VERSION ""

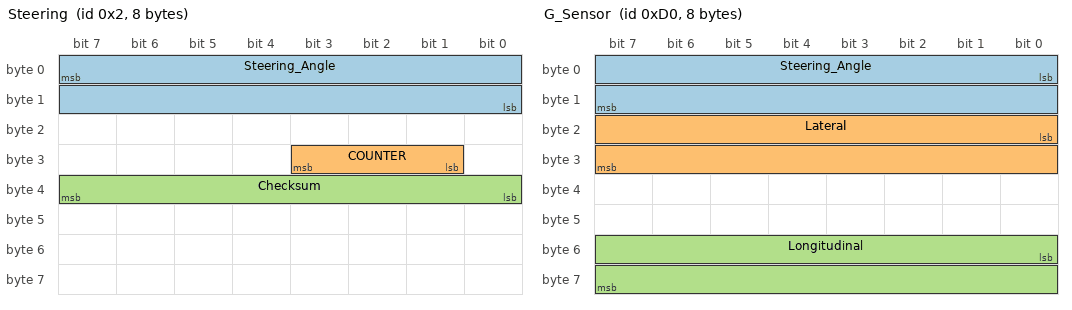
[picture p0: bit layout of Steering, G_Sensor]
BO_ 2 Steering: 8 XXX
 SG_ Steering_Angle : 7|16@0- (0.1,0) [-500|500] "degree" XXX
 SG_ COUNTER : 27|3@0+ (1,0) [0|7] "" XXX
 SG_ Checksum : 39|8@0+ (1,0) [0|255] "" XXX

BO_ 208 G_Sensor: 8 XXX
 SG_ Steering_Angle : 0|16@1- (-0.1,0) [-500|500] "" XXX
 SG_ Lateral : 16|16@1- (-0.0035,1) [-255|255] "" XXX
 SG_ Longitudinal : 48|16@1- (-0.00035,0) [-255|255] "" XXX

BO_ 209 Brake_Pedal: 8 XXX
 SG_ Speed : 0|16@1+ (0.05625,0) [0|255] "KPH" XXX
 SG_ Brake_Pedal : 16|8@1+ (1,0) [0|255] "" XXX

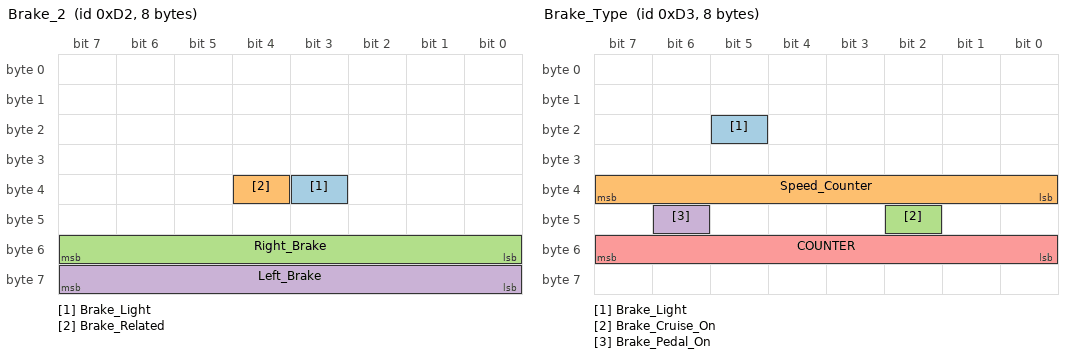
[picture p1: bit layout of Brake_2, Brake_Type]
BO_ 210 Brake_2: 8 XXX
 SG_ Brake_Light : 35|1@1+ (1,0) [0|1] "" XXX
 SG_ Brake_Related : 36|1@1+ (1,0) [0|1] "" XXX
 SG_ Right_Brake : 48|8@1+ (1,0) [0|255] "" XXX
 SG_ Left_Brake : 56|8@1+ (1,0) [0|255] "" XXX

BO_ 211 Brake_Type: 8 XXX
 SG_ Brake_Light : 21|1@1+ (1,0) [0|1] "" XXX
 SG_ Speed_Counter : 32|8@1+ (1,0) [0|255] "" XXX
 SG_ Brake_Cruise_On : 42|1@1+ (1,0) [0|1] "" XXX
 SG_ Brake_Pedal_On : 46|1@1+ (1,0) [0|1] "" XXX
 SG_ COUNTER : 48|8@1+ (1,0) [0|255] "" XXX

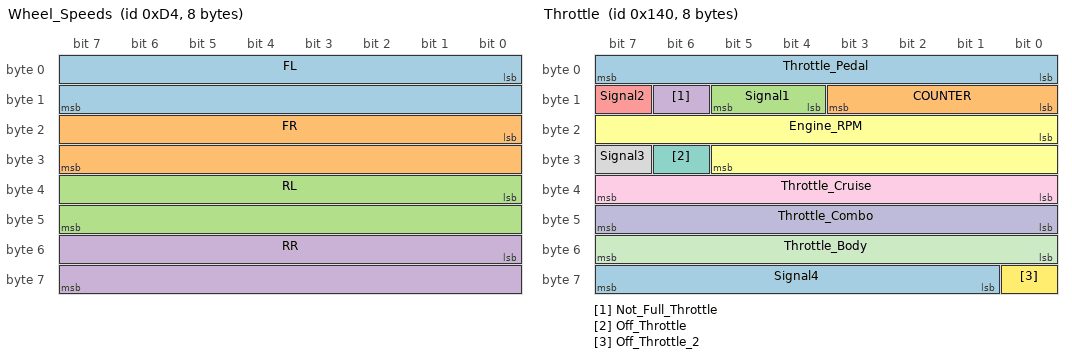
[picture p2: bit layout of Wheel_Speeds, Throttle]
BO_ 212 Wheel_Speeds: 8 XXX
 SG_ FL : 0|16@1+ (0.0592,0) [0|255] "KPH" XXX
 SG_ FR : 16|16@1+ (0.0592,0) [0|255] "KPH" XXX
 SG_ RL : 32|16@1+ (0.0592,0) [0|255] "KPH" XXX
 SG_ RR : 48|16@1+ (0.0592,0) [0|255] "KPH" XXX

BO_ 320 Throttle: 8 XXX
 SG_ Throttle_Pedal : 0|8@1+ (0.392157,0) [0|255] "" XXX
 SG_ COUNTER : 8|4@1+ (1,0) [0|15] "" XXX
 SG_ Signal1 : 12|2@1+ (1,0) [0|7] "" XXX
 SG_ Not_Full_Throttle : 14|1@1+ (1,0) [0|1] "" XXX
 SG_ Signal2 : 15|1@1+ (1,0) [0|1] "" XXX
 SG_ Engine_RPM : 16|14@1+ (1,0) [0|32767] "" XXX
 SG_ Off_Throttle : 30|1@1+ (1,0) [0|1] "" XXX
 SG_ Signal3 : 31|1@1+ (1,0) [0|1] "" XXX
 SG_ Throttle_Cruise : 32|8@1+ (1,0) [0|255] "" XXX
 SG_ Throttle_Combo : 40|8@1+ (1,0) [0|255] "" XXX
 SG_ Throttle_Body : 48|8@1+ (1,0) [0|255] "" XXX
 SG_ Off_Throttle_2 : 56|1@1+ (1,0) [0|1] "" XXX
 SG_ Signal4 : 57|7@1+ (1,0) [0|127] "" XXX

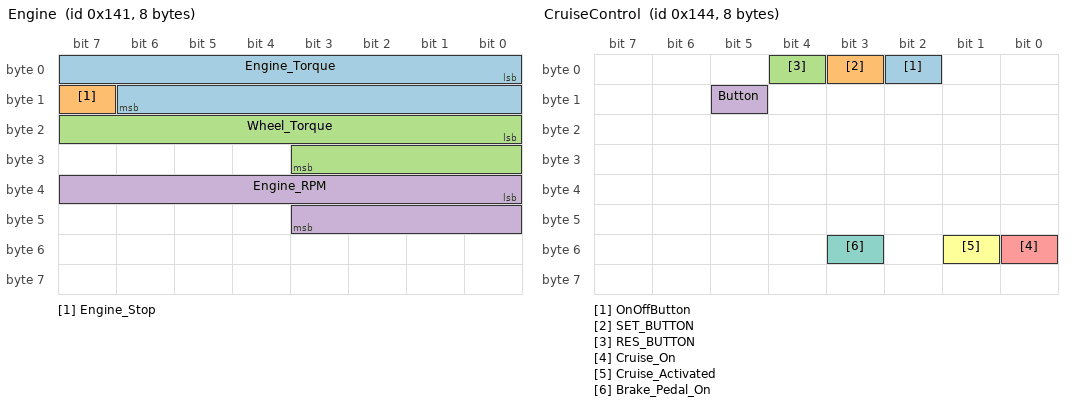
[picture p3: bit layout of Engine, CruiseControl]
BO_ 321 Engine: 8 XXX
 SG_ Engine_Torque : 0|15@1+ (1,0) [0|255] "" XXX
 SG_ Engine_Stop : 15|1@1+ (1,0) [0|1] "" XXX
 SG_ Wheel_Torque : 16|12@1+ (1,0) [0|4095] "" XXX
 SG_ Engine_RPM : 32|12@1+ (1,0) [0|8191] "" XXX

BO_ 324 CruiseControl: 8 XXX
 SG_ OnOffButton : 2|1@1+ (1,0) [0|1] "" XXX
 SG_ SET_BUTTON : 3|1@1+ (1,0) [0|1] "" XXX
 SG_ RES_BUTTON : 4|1@1+ (1,0) [0|1] "" XXX
 SG_ Button : 13|1@1+ (1,0) [0|1] "" XXX
 SG_ Cruise_On : 48|1@1+ (1,0) [0|1] "" XXX
 SG_ Cruise_Activated : 49|1@1+ (1,0) [0|1] "" XXX
 SG_ Brake_Pedal_On : 51|1@1+ (1,0) [0|1] "" XXX

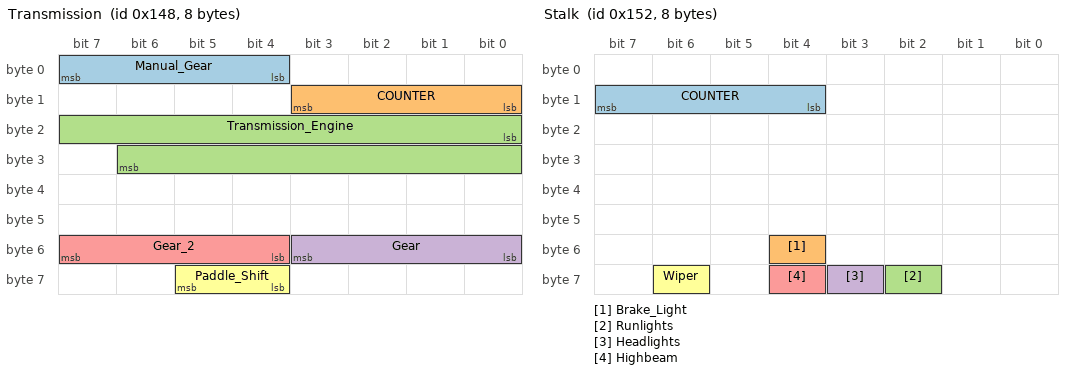
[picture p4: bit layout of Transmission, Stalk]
BO_ 328 Transmission: 8 XXX
 SG_ Manual_Gear : 4|4@1+ (1,0) [0|15] "" XXX
 SG_ COUNTER : 8|4@1+ (1,0) [0|15] "" XXX
 SG_ Transmission_Engine : 16|15@1+ (1,0) [0|65535] "" XXX
 SG_ Gear : 48|4@1+ (1,0) [0|15] "" XXX
 SG_ Gear_2 : 52|4@1+ (1,0) [0|15] "" XXX
 SG_ Paddle_Shift : 60|2@1+ (1,0) [0|3] "" XXX

BO_ 329 CVT_Ratio: 8 XXX

BO_ 336 Brake_Pressure: 8 XXX
 SG_ Brake_Pressure_Right : 0|8@1+ (1,0) [0|255] "" XXX
 SG_ Brake_Pressure_Left : 8|8@1+ (1,0) [0|255] "" XXX

BO_ 338 Stalk: 8 XXX
 SG_ COUNTER : 12|4@1+ (1,0) [0|15] "" XXX
 SG_ Brake_Light : 52|1@1+ (1,0) [0|1] "" XXX
 SG_ Runlights : 58|1@1+ (1,0) [0|1] "" XXX
 SG_ Headlights : 59|1@1+ (1,0) [0|1] "" XXX
 SG_ Highbeam : 60|1@1+ (1,0) [0|1] "" XXX
 SG_ Wiper : 62|1@1+ (1,0) [0|1] "" XXX

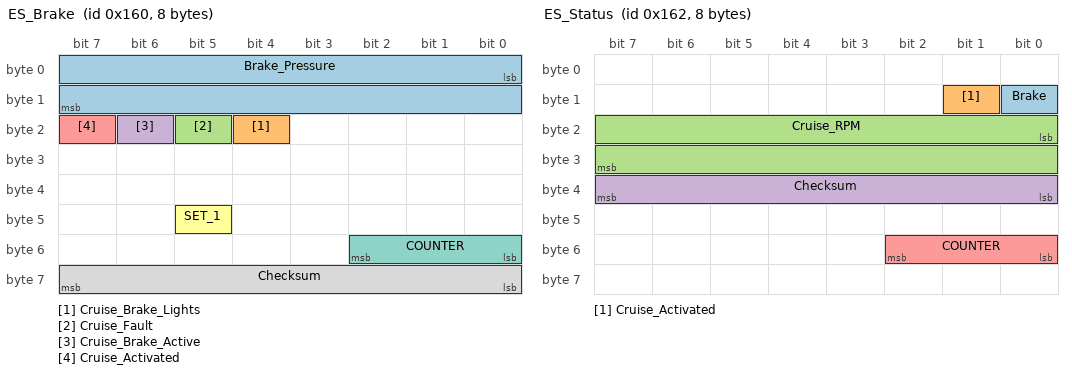
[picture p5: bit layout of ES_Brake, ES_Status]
BO_ 352 ES_Brake: 8 XXX
 SG_ Brake_Pressure : 0|16@1+ (1,0) [0|255] "" XXX
 SG_ Cruise_Brake_Lights : 20|1@1+ (1,0) [0|1] "" XXX
 SG_ Cruise_Fault : 21|1@1+ (1,0) [0|1] "" XXX
 SG_ Cruise_Brake_Active : 22|1@1+ (1,0) [0|1] "" XXX
 SG_ Cruise_Activated : 23|1@1+ (1,0) [0|1] "" XXX
 SG_ SET_1 : 45|1@0+ (1,0) [0|1] "" XXX
 SG_ COUNTER : 48|3@1+ (1,0) [0|7] "" XXX
 SG_ Checksum : 56|8@1+ (1,0) [0|255] "" XXX

BO_ 353 ES_Distance: 8 XXX
 SG_ Cruise_Throttle : 0|12@1+ (1,0) [0|4095] "" XXX
 SG_ Signal1 : 12|4@1+ (1,0) [0|15] "" XXX
 SG_ Car_Follow : 16|1@1+ (1,0) [0|1] "" XXX
 SG_ Signal2 : 17|3@1+ (1,0) [0|7] "" XXX
 SG_ Cruise_Brake_Active : 20|1@1+ (1,0) [0|1] "" XXX
 SG_ Distance_Swap : 21|1@1+ (1,0) [0|1] "" XXX
 SG_ Standstill : 22|1@1+ (1,0) [0|1] "" XXX
 SG_ Signal3 : 23|1@1+ (1,0) [0|1] "" XXX
 SG_ Close_Distance : 24|8@1+ (0.019607,0) [0|5] "m" XXX
 SG_ Signal4 : 32|9@1+ (1,0) [0|255] "" XXX
 SG_ Standstill_2 : 41|1@1+ (1,0) [0|1] "" XXX
 SG_ Cruise_Fault : 42|1@1+ (1,0) [0|1] "" XXX
 SG_ Signal5 : 43|1@1+ (1,0) [0|1] "" XXX
 SG_ COUNTER : 44|3@1+ (1,0) [0|7] "" XXX
 SG_ Signal6 : 47|1@1+ (1,0) [0|1] "" XXX
 SG_ Cruise_Button : 48|3@1+ (1,0) [0|7] "" XXX
 SG_ Signal7 : 51|5@1+ (1,0) [0|31] "" XXX
 SG_ Checksum : 56|8@1+ (1,0) [0|255] "" XXX

BO_ 354 ES_Status: 8 XXX
 SG_ Brake : 8|1@1+ (1,0) [0|1] "" XXX
 SG_ Cruise_Activated : 9|1@1+ (1,0) [0|1] "" XXX
 SG_ Cruise_RPM : 16|16@1+ (1,0) [0|65535] "" XXX
 SG_ Checksum : 32|8@1+ (1,0) [0|255] "" XXX
 SG_ COUNTER : 48|3@1+ (1,0) [0|7] "" XXX

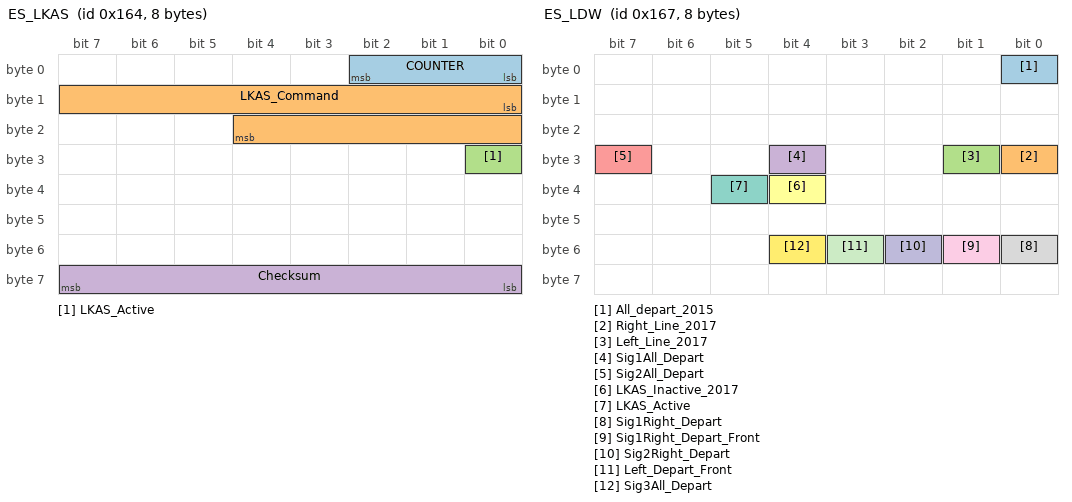
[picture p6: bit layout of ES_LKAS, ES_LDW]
BO_ 356 ES_LKAS: 8 XXX
 SG_ COUNTER : 0|3@1+ (1,0) [0|7] "" XXX
 SG_ LKAS_Command : 8|13@1- (-1,0) [-4096|4096] "" XXX
 SG_ LKAS_Active : 24|1@1+ (1,0) [0|1] "" XXX
 SG_ Checksum : 56|8@1+ (1,0) [0|255] "" XXX

BO_ 359 ES_LDW: 8 XXX
 SG_ All_depart_2015 : 0|1@1+ (1,0) [0|1] "" XXX
 SG_ Right_Line_2017 : 24|1@1+ (1,0) [0|1] "" XXX
 SG_ Left_Line_2017 : 25|1@1+ (1,0) [0|1] "" XXX
 SG_ Sig1All_Depart : 28|1@1+ (1,0) [0|1] "" XXX
 SG_ Sig2All_Depart : 31|1@1+ (1,0) [0|1] "" XXX
 SG_ LKAS_Inactive_2017 : 36|1@1+ (1,0) [0|1] "" XXX
 SG_ LKAS_Active : 37|1@1+ (1,0) [0|1] "" XXX
 SG_ Sig1Right_Depart : 48|1@1+ (1,0) [0|1] "" XXX
 SG_ Sig1Right_Depart_Front : 49|1@1+ (1,0) [0|1] "" XXX
 SG_ Sig2Right_Depart : 50|1@1+ (1,0) [0|1] "" XXX
 SG_ Left_Depart_Front : 51|1@1+ (1,0) [0|1] "" XXX
 SG_ Sig3All_Depart : 52|1@1+ (1,0) [0|1] "" XXX

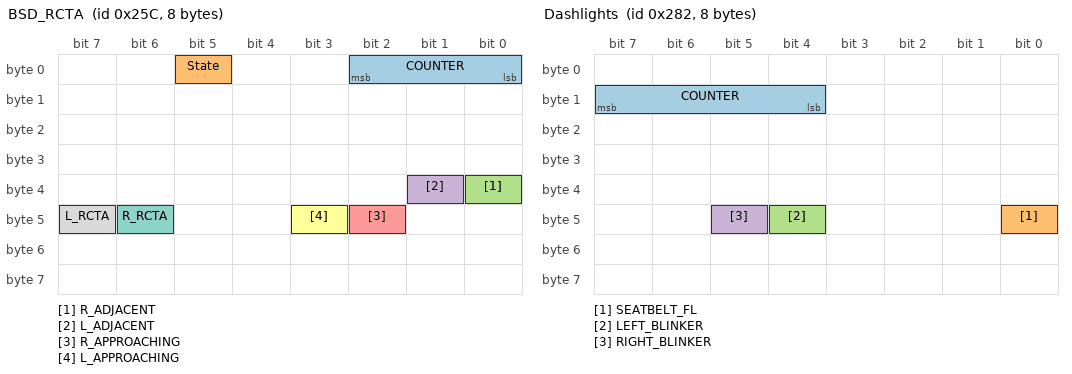
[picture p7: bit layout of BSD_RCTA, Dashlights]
BO_ 604 BSD_RCTA: 8 XXX
 SG_ COUNTER : 0|3@1+ (1,0) [0|7] "" XXX
 SG_ State : 5|1@1+ (1,0) [0|1] "" XXX
 SG_ R_ADJACENT : 32|1@1+ (1,0) [0|1] "" XXX
 SG_ L_ADJACENT : 33|1@1+ (1,0) [0|1] "" XXX
 SG_ R_APPROACHING : 42|1@1+ (1,0) [0|1] "" XXX
 SG_ L_APPROACHING : 43|1@1+ (1,0) [0|1] "" XXX
 SG_ R_RCTA : 46|1@1+ (1,0) [0|1] "" XXX
 SG_ L_RCTA : 47|1@1+ (1,0) [0|1] "" XXX

BO_ 642 Dashlights: 8 XXX
 SG_ COUNTER : 12|4@1+ (1,0) [0|15] "" XXX
 SG_ SEATBELT_FL : 40|1@1+ (1,0) [0|1] "" XXX
 SG_ LEFT_BLINKER : 44|1@1+ (1,0) [0|1] "" XXX
 SG_ RIGHT_BLINKER : 45|1@1+ (1,0) [0|1] "" XXX

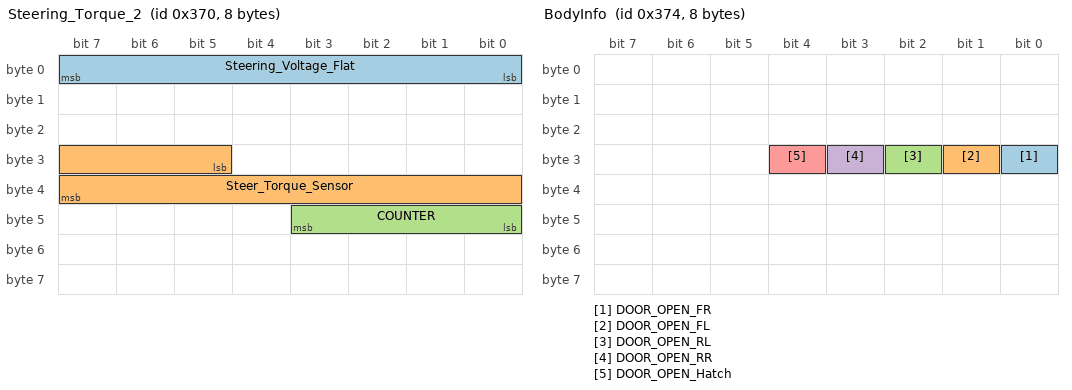
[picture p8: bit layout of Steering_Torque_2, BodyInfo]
BO_ 880 Steering_Torque_2: 8 XXX
 SG_ Steering_Voltage_Flat : 0|8@1+ (1,0) [0|255] "" XXX
 SG_ Steer_Torque_Sensor : 29|11@1- (-1,0) [-1000|1000] "" XXX
 SG_ COUNTER : 40|4@1+ (1,0) [0|15] "" XXX

BO_ 884 BodyInfo: 8 XXX
 SG_ DOOR_OPEN_FR : 24|1@1+ (1,0) [0|1] "" XXX
 SG_ DOOR_OPEN_FL : 25|1@1+ (1,0) [0|1] "" XXX
 SG_ DOOR_OPEN_RL : 26|1@1+ (1,0) [0|1] "" XXX
 SG_ DOOR_OPEN_RR : 27|1@1+ (1,0) [0|1] "" XXX
 SG_ DOOR_OPEN_Hatch : 28|1@1+ (1,0) [0|1] "" XXX

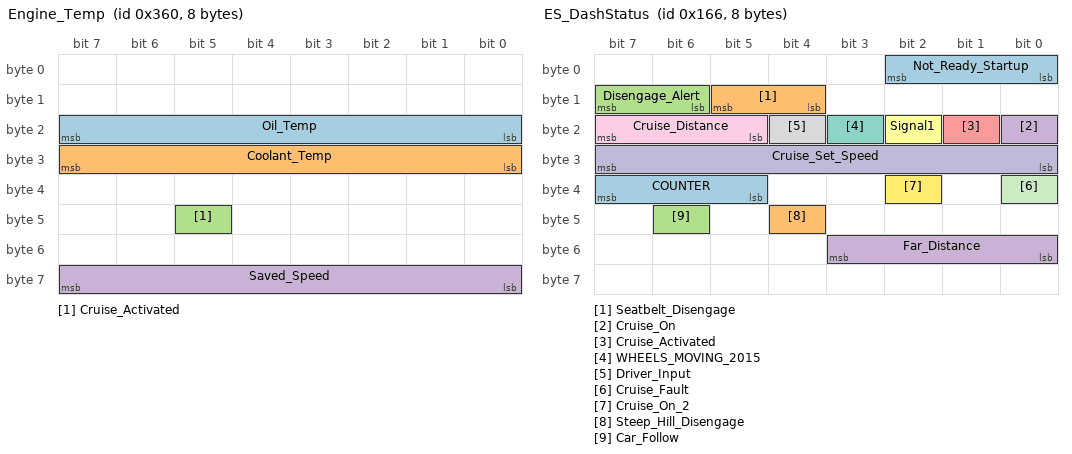
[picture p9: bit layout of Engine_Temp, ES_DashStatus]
BO_ 864 Engine_Temp: 8 XXX
 SG_ Oil_Temp : 16|8@1+ (1,-40) [0|255] "" XXX
 SG_ Coolant_Temp : 24|8@1+ (1,-40) [0|255] "" XXX
 SG_ Cruise_Activated : 45|1@1+ (1,0) [0|1] "" XXX
 SG_ Saved_Speed : 56|8@1+ (1,0) [0|255] "" XXX

BO_ 866 Fuel: 8 XXX

BO_ 977 Dash_State2: 8 XXX
 SG_ UNITS : 15|1@1+ (1,0) [0|1] "" XXX

BO_ 1745 Dash_State: 8 XXX
 SG_ Units : 15|1@1+ (1,0) [0|1] "" XXX

BO_ 358 ES_DashStatus: 8 XXX
 SG_ Not_Ready_Startup : 0|3@1+ (1,0) [0|7] "" XXX
 SG_ Seatbelt_Disengage : 12|2@1+ (1,0) [0|3] "" XXX
 SG_ Disengage_Alert : 14|2@1+ (1,0) [0|3] "" XXX
 SG_ Cruise_On : 16|1@1+ (1,0) [0|1] "" XXX
 SG_ Cruise_Activated : 17|1@1+ (1,0) [0|1] "" XXX
 SG_ Signal1 : 18|1@1+ (1,0) [0|1] "" XXX
 SG_ WHEELS_MOVING_2015 : 19|1@1+ (1,0) [0|1] "" XXX
 SG_ Driver_Input : 20|1@1+ (1,0) [0|1] "" XXX
 SG_ Cruise_Distance : 21|3@1+ (1,0) [0|7] "" XXX
 SG_ Cruise_Set_Speed : 24|8@1+ (1,0) [0|255] "" XXX
 SG_ Cruise_Fault : 32|1@1+ (1,0) [0|1] "" XXX
 SG_ Cruise_On_2 : 34|1@1+ (1,0) [0|1] "" XXX
 SG_ COUNTER : 37|3@1+ (1,0) [0|7] "" XXX
 SG_ Steep_Hill_Disengage : 44|1@1+ (1,0) [0|3] "" XXX
 SG_ Car_Follow : 46|1@1+ (1,0) [0|1] "" XXX
 SG_ Far_Distance : 48|4@1+ (5,0) [0|75] "m" XXX

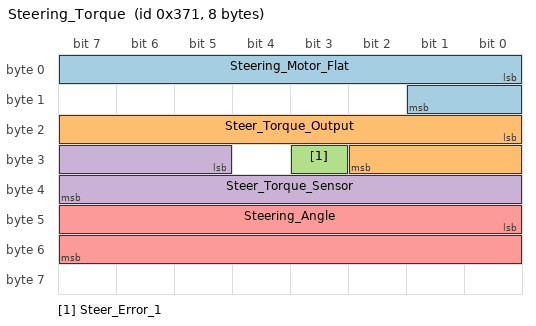
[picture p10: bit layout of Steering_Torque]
BO_ 881 Steering_Torque: 8 XXX
 SG_ Steering_Motor_Flat : 0|10@1+ (32,0) [0|1000] "" XXX
 SG_ Steer_Torque_Output : 16|11@1- (-32,0) [-1000|1000] "" XXX
 SG_ Steer_Error_1 : 27|1@1+ (1,0) [0|1] "" XXX
 SG_ Steer_Torque_Sensor : 29|11@1- (1,0) [-1000|1000] "" XXX
 SG_ Steering_Angle : 40|16@1- (-0.033,0) [-600|600] "" XXX

BU_: K16_BECM K73_TCIC K9_BCM K43_PSCM K17_EBCM K20_ECM K114B_HPCM NEO K124_ASCM EPB
VAL_TABLE_ TurnSignals 2 "Right Turn" 1 "Left Turn" 0 "None" ;
VAL_TABLE_ Intellibeam 1 "Active" 0 "Inactive" ;
VAL_TABLE_ HighBeamsActive 1 "Active" 0 "Inactive" ;
VAL_TABLE_ HighBeamsTemporary 1 "Active" 0 "Inactive" ;
VAL_TABLE_ ACCLeadCar 1 "Present" 0 "Not Present" ;
VAL_TABLE_ ACCCmdActive 1 "Active" 0 "Inactive" ;
VAL_TABLE_ BrakePedalPressed 1 "Pressed" 0 "Depressed" ;
VAL_TABLE_ DistanceButton 1 "Active" 0 "Inactive" ;
VAL_TABLE_ LKAButton 1 "Active" 0 "Inactive" ;
VAL_TABLE_ ACCButtons 6 "Cancel" 5 "Main" 3 "Set" 2 "Resume" 1 "None" ;
VAL_TABLE_ DriveModeButton 1 "Active" 0 "Inactive" ;
VAL_TABLE_ PRNDL 3 "Reverse" 2 "Drive" 1 "Neutral" 0 "Park" ;
VAL_TABLE_ ESPButton 1 "Active" 0 "Inactive" ;
VAL_TABLE_ DoorStatus 1 "Opened" 0 "Closed" ;
VAL_TABLE_ SeatBeltStatus 1 "Latched" 0 "Unlatched" ;
VAL_TABLE_ LKASteeringCmdActive 1 "Active" 0 "Inactive" ;
VAL_TABLE_ ACCGapLevel 3 "Far" 2 "Med" 1 "Near" 0 "Inactive" ;
VAL_TABLE_ GasRegenCmdActiveInv 1 "Inactive" 0 "Active" ;
VAL_TABLE_ GasRegenCmdActive 1 "Active" 0 "Inactive" ;
VAL_TABLE_ LKATorqueDeliveredStatus 3 "Failed" 2 "Temp. Limited" 1 "Active" 0 "Inactive" ;
VAL_TABLE_ HandsOffSWDetectionStatus 1 "Hands On" 0 "Hands Off" ;
VAL_TABLE_ HandsOffSWDetectionMode 2 "Failed" 1 "Enabled" 0 "Disabled" ;

CM_ "AUTOGENERATED FILE, DO NOT EDIT";

CM_ "Imported file _comma.dbc starts here";
CM_ "BO_ STEERING_IPAS_COMMA: Copy of msg 614 so we can do angle control while the Park Assist ECU is connected (Panda spoofs 614 with 359 on connector J70). Note that addresses 0x266 and 0x167 are checksum-invariant";

CM_ "BO_ SECONDARY_STEER_ANGLE: ZSS is a high-precision steering angle sensor that can replace the lower resolution sensor in most TSS1 Toyotas. Learn more: https://github.com/commaai/openpilot/wiki/Toyota-Lexus#zorro-steering-sensor-zss";

CM_ "BO_ SDSU: The sDSU is a modified DSU for use in TSS1 Toyotas. Learn more: https://github.com/wocsor/panda/tree/smart_dsu";
CM_ SG_ 767 FD_BUTTON "The follow distance button signal as forwarded by the sdsu";

CM_ "Imported file _toyota_2017.dbc starts here";
CM_ SG_ 36 YAW_RATE "verify";
CM_ SG_ 36 ACCEL_X "x-axis accel";
CM_ SG_ 37 STEER_FRACTION "1/15th of the signal STEER_ANGLE, which is 1.5 deg; note that 0x8 is never set";
CM_ SG_ 37 STEER_RATE "factor is tbd";
CM_ SG_ 466 NEUTRAL_FORCE "force in newtons the engine/electric motors are applying without any acceleration commands or user input";
CM_ SG_ 466 ACC_BRAKING "whether brakes are being actuated from ACC command";
CM_ SG_ 466 ACCEL_NET "net acceleration produced by the system, given ACCEL_CMD, road grade and other factors";
CM_ SG_ 466 CRUISE_STATE "Active state is 8, if standstill is requested will switch to state 11(3 sec timer), after timer is elapsed will switch into state 7(standstill). If plus button was pressed - status 9, minus button pressed - status 10";
CM_ SG_ 467 ACC_FAULTED "1 when ACC is faulted and the PCM disallows engagement";
CM_ SG_ 467 SET_SPEED "43 km/h are shown as 28 mph, so conversion isn't perfect";
CM_ SG_ 467 LOW_SPEED_LOCKOUT "in low speed lockout, system would always disengage below 28mph";
CM_ SG_ 560 BRAKE_PRESSED "another brake pressed?";
CM_ SG_ 581 GAS_PEDAL "it seems slightly filtered";
CM_ SG_ 608 STEER_TORQUE_DRIVER "driver torque";
CM_ SG_ 608 STEER_OVERRIDE "set when driver torque exceeds a certain value";
CM_ SG_ 614 ANGLE "set to measured angle when ipas control isn't active";
CM_ SG_ 643 _COUNTER "only used on cars that use this msg for cruise control";
CM_ SG_ 643 BRAKE_STATUS "only used on cars that use this msg for cruise control";
CM_ SG_ 643 PRECOLLISION_ACTIVE "set 0.5s before any braking";
CM_ SG_ 835 ACC_TYPE "if 2, car is likely to have a permanent low speed lockout. 1 is ok";
CM_ SG_ 835 RADAR_DIRTY "Display Clean Radar Sensor message on HUD";
CM_ SG_ 835 ACC_MALFUNCTION "display ACC fault on dash if set to 1";
CM_ SG_ 835 ACC_CUT_IN "Display blinking yellow lead if set to 1";
CM_ SG_ 835 DISTANCE "Cycle through ACC following distance from long, mid, short when set to 1";
CM_ SG_ 835 ITS_CONNECT_LEAD "Displayed when lead car is capable of ITS Connect";
CM_ SG_ 835 ALLOW_LONG_PRESS "Enable Toyota's factory set speed increment behaviour, available on both metrics cars and imperial unit cars";
CM_ SG_ 835 PERMIT_BRAKING "Original ACC has this going high when a car in front is detected. In openpilot and before the PERMIT_BRAKING name, this was 'SET_ME_1' and is hardcoded to be high. Unsure if only informational or has an effect though existing usage in openpilot is to always set it to 1. Originally 'PMTBRKG' in the leaked toyota_2017_ref_pt.dbc file and name expansion speculated to be PerMiT BRaKinG.";
CM_ SG_ 835 ACCEL_CMD_ALT "Copy of main ACCEL_CMD, but across 8 bits instead of 16 bits like ACCEL_CMD. Unsure if only informational or has an effect. Likely informational as existing openpilot sets this to 0 and no loss of functionality observed. Originally 'AT_RAW' in leaked toyota_2017_ref_pt.dbc file.";
CM_ SG_ 865 GAS_PEDAL_ALT "copy of main GAS_PEDAL. Both use 8 bits. Might indicate that this message is for pedals.";
CM_ SG_ 865 CLUTCH_RELEASED "boolean of clutch for 6MT.";
CM_ SG_ 865 ACC_FAULTED "1 when ACC is faulted and the PCM disallows engagement. Also describes a lockout when the ACC_CONTROL->ACC_MALFUNCTION bit is set.";
CM_ SG_ 921 UI_SET_SPEED "set speed shown in the vehicle's UI with the vehicle's unit";
CM_ SG_ 921 TEMP_ACC_FAULTED "1 when the UI is displaying or playing fault-related alerts or sounds. Also 1 when pressing main on.";
CM_ SG_ 951 BRAKE_LIGHTS_ACC "brake lights when ACC commands decel";
CM_ SG_ 956 GEAR "on 6MT, only R shows.";
CM_ SG_ 1009 UI_SET_SPEED "units seem to be whatever the car is set to";
CM_ SG_ 1041 PCS_INDICATOR "Pre-Collision System Indicator";
CM_ SG_ 1041 PCS_SENSITIVITY "Pre-Collision System Sensitivity";
CM_ SG_ 1041 PCS_DUST "alert: Front Camera Low Visibility Unavailable See Owner's Manual";
CM_ SG_ 1041 PCS_DUST2 "alert: Pre-Collision System Radar Sensor Blocked Unavailable Clean Radar Sensor";
CM_ SG_ 1041 PCS_TEMP "alert: Front Camera Out of Temperature Range Unavailable Wait until Normal Temperature";
CM_ SG_ 1041 PCS_TEMP2 "alert: Pre-Collision System Out of Temperature Range Unavailable See Owner's Manual";
CM_ SG_ 1041 FRD_ADJ "alert: ERROR ADJUSTING FRONT RADAR BEAM";
CM_ SG_ 1042 LDA_SA_TOGGLE "LDA Steering Assist Toggle";
CM_ SG_ 1042 LDW_EXIST "Unclear what this is, it's usually set to 0";
CM_ SG_ 1042 LDA_SENSITIVITY "LDA Sensitivity";
CM_ SG_ 1042 LDA_ON_MESSAGE "Display LDA Turned ON message";
CM_ SG_ 1042 REPEATED_BEEPS "LDA audible warning";
CM_ SG_ 1042 LDA_UNAVAILABLE_QUIET "LDA toggles and sensitivity settings are greyed out if set to 1";
CM_ SG_ 1042 LDA_MESSAGES "Various LDA Messages";
CM_ SG_ 1042 LDA_FRONT_CAMERA_BLOCKED "originally LDAFCVB, LDA related settings are greyed out if set to 1";
CM_ SG_ 1042 TAKE_CONTROL "Please Control Steering Wheel warning";
CM_ SG_ 1042 LANE_SWAY_TOGGLE "Lane Sway Warning System SWS Switch";
CM_ SG_ 1042 LANE_SWAY_WARNING "Lane Sway Warning System Triggered";
CM_ SG_ 1042 LANE_SWAY_FLD "Unknown signal for Lane Sway Warning System, set to 7 on stock system when SWS is enabled, 0 when SWS is disabled";
CM_ SG_ 1042 LANE_SWAY_BUZZER "Similar to TWO_BEEPS";
CM_ SG_ 1042 SET_ME_X01 "empty bit on leaked dbc, always set to 1 during normal operations";
CM_ SG_ 1042 SET_ME_X02 "empty bit on leaked dbc, always set to 2 during normal operations";
CM_ SG_ 1083 STATE "when the dashboard button is pressed, the value changes from zero to non-zero";
CM_ SG_ 1161 SPDVAL1 "Numbers 0-199 is displayed, 200-254 displays circle without number and 255 is for no limit.";
CM_ SG_ 1161 SYNCID1 "counter from 1 to f at 1 Hz";
CM_ SG_ 1161 SPDVAL2 "conditional speed value 70";
CM_ SG_ 1162 SGNNUMP "1 if SPDVAL1 is set, otherwise 0";
CM_ SG_ 1162 SYNCID2 "counter from 1 to f at 1 Hz";
CM_ SG_ 1163 TSREQPD "always 1";
CM_ SG_ 1163 TSRMSW "always 1";
CM_ SG_ 1163 OTSGNNTM "always 3";
CM_ SG_ 1163 NTLVLSPD "always 3";
CM_ SG_ 1163 OVSPNTM "always 3";
CM_ SG_ 1163 OVSPVALL "-5 at start then 2 after 2 seconds";
CM_ SG_ 1163 OVSPVALM "-5 at start then 5 after 2 seconds";
CM_ SG_ 1163 OVSPVALH "-5 at start then 10 after 2 seconds";
CM_ SG_ 1163 TSRSPU "always 1";
CM_ SG_ 1552 UI_SPEED "Does not appear to match dash";
CM_ SG_ 1552 METER_SLIDER_BRIGHTNESS_PCT "Combination display brightness setting, scales from 12 per cent to 100 per cent, reflects combination meter settings only, not linked with headlight state";
CM_ SG_ 1552 METER_SLIDER_LOW_BRIGHTNESS "Combination display low brightness mode, also controls footwell lighting";
CM_ SG_ 1552 METER_SLIDER_DIMMED "Combination display slider not at max, reflects combination meter settings only, not linked with headlight state";
CM_ SG_ 1553 ODOMETER "Unit is dependent upon units signal";
CM_ SG_ 1592 LOCK_STATUS_CHANGED "1 on rising edge of lock/unlocking";
CM_ SG_ 1592 LOCK_STATUS "The next 3 bits always seem to follow this signal.";
CM_ SG_ 1592 LOCKED_VIA_KEYFOB "1 for as long as car is locked with key fob or door handle touch";

CM_ "toyota_tnga_k_pt.dbc starts here";

CM_ SG_ 550 BRAKE_PRESSURE "seems prop to pedal force";
CM_ SG_ 550 BRAKE_POSITION "seems proportional to pedal displacement, unclear the max value of 0x1c8";
CM_ SG_ 610 TYPE "seems 1 on Corolla, 0 on all others";

VAL_ 513 STATE 5 "FAULT_TIMEOUT" 4 "FAULT_STARTUP" 3 "FAULT_SCE" 2 "FAULT_SEND" 1 "FAULT_BAD_CHECKSUM" 0 "NO_FAULT" ;

VAL_ 295 GEAR 0 "P" 1 "R" 2 "N" 3 "D" 4 "B";
VAL_ 466 CRUISE_STATE 11 "timer_3sec" 10 "adaptive click down" 9 "adaptive click up" 8 "adaptive engaged" 7 "standstill" 6 "non-adaptive click up" 5 "non-adaptive click down" 4 "non-adaptive hold down" 3 "non-adaptive hold up" 2 "non-adaptive being engaged" 1 "non-adaptive engaged" 0 "off";
VAL_ 467 LOW_SPEED_LOCKOUT 2 "low speed locked" 1 "ok";
VAL_ 467 PCM_FOLLOW_DISTANCE 1 "far" 2 "medium" 3 "close";
VAL_ 614 STATE 3 "enabled" 1 "disabled";
VAL_ 614 DIRECTION_CMD 3 "right" 2 "center" 1 "left";
VAL_ 643 STATE 0 "normal" 1 "adaptive_cruise_control" 3 "emergency_braking";
VAL_ 835 ACC_TYPE 2 "permanent low speed lockout" 1 "ok";
VAL_ 835 ACC_MALFUNCTION 1 "faulted" 0 "ok";
VAL_ 835 ACC_CUT_IN 1 "CUT-IN Detected" 0 "clear";
VAL_ 835 ALLOW_LONG_PRESS 2 "set speed increase by 5 speed units regardless" 1 "set speed increase by 1 speed unit on short press, 5 speed units on long press";
VAL_ 865 CLUTCH_RELEASED 0 "clutch pressed any amount" 1 "clutch released"
VAL_ 921 CRUISE_CONTROL_STATE 2 "disabled" 11 "hold" 10 "hold_waiting_user_cmd" 6 "enabled" 5 "faulted";
VAL_ 956 SPORT_ON 0 "off" 1 "on";
VAL_ 956 GEAR 0 "D" 1 "S" 8 "N" 16 "R" 32 "P";
VAL_ 956 SPORT_GEAR_ON 0 "off" 1 "on";
VAL_ 956 SPORT_GEAR 1 "S1" 2 "S2" 3 "S3" 4 "S4" 5 "S5" 6 "S6";
VAL_ 956 ECON_ON 0 "off" 1 "on";
VAL_ 956 B_GEAR_ENGAGED 0 "off" 1 "on";
VAL_ 956 DRIVE_ENGAGED 0 "off" 1 "on";
VAL_ 1005 REVERSE_CAMERA_GUIDELINES 3 "No guidelines" 2 "Static guidelines" 1 "Active guidelines";
VAL_ 1009 PCM_FOLLOW_DISTANCE 1 "far" 2 "medium" 3 "close";
VAL_ 1041 PCS_INDICATOR 2 "PCS Faulted" 1 "PCS Turned Off By User" 0 "PCS Enabled";
VAL_ 1041 PCS_SENSITIVITY 64 "high sensitivity"  128 "mid sensitivity" 192 "low sensitivity" 0 "off";
VAL_ 1042 LDA_ALERT 3 "hold with continuous beep" 2 "LDA unavailable" 1 "hold" 0 "none";
VAL_ 1042 BARRIERS 3 "left" 2 "right" 1 "both" 0 "none";
VAL_ 1042 RIGHT_LINE 3 "orange" 2 "faded" 1 "solid" 0 "none";
VAL_ 1042 LKAS_STATUS 1 "on" 0 "off";
VAL_ 1042 LEFT_LINE 3 "orange" 2 "faded" 1 "solid" 0 "none";
VAL_ 1042 LDA_ON_MESSAGE 2 "Lane Departure Alert Turned ON, Steering Assist Inactive" 1 "Lane Departure Alert Turned ON, Steering Assist Active" 0 "clear";
VAL_ 1042 LDA_SA_TOGGLE  2 "steering assist off" 1 "steering assist on";
VAL_ 1042 LDA_SENSITIVITY 2 "standard" 1 "high" 0 "undefined";
VAL_ 1042 LDA_MESSAGES 4 "lda unavailable at this speed" 1 "lda unavailable below approx 50km/h" 0 "ok";
VAL_ 1042 LDA_FRONT_CAMERA_BLOCKED 1 "lda unavailable" 0 "ok";
VAL_ 1042 TAKE_CONTROL 1 "take control" 0 "ok";
VAL_ 1042 LANE_SWAY_WARNING 3 "ok" 2 "orange please take a break" 1 "prompt would you like to take a break" 0 "ok";
VAL_ 1042 LANE_SWAY_BUZZER 3 "ok" 2 "beep twice" 1 "beep twice" 0 "ok";
VAL_ 1161 TSGN1 1 "speed sign" 0 "none";
VAL_ 1161 TSGN2 1 "speed sign" 0 "none";
VAL_ 1161 SPLSGN2 15 "conditional blank" 4 "wet road" 5 "rain" 0 "none";
VAL_ 1162 TSGN3 0 "none" 1 "speed sign" 2 "0 unlimited" 7 "unlimited" 16 "highway" 17 "no highway" 18 "motorway" 19 "no motorway" 20 "in city" 21 "outside city" 22 "pedestrian area" 23 "no pedestrian area" 65 "no overtaking left" 66 "no overtaking right" 67 "overtaking allowed again" 81 "no right turn" 97 "stop" 105 "yield" 113 "stop" 114 "yield us" 129 "no entry" 138 "no entry tss2" 145 "do not enter";
VAL_ 1162 SPLSGN3 15 "conditional blank" 4 "wet road" 5 "rain" 0 "none";
VAL_ 1552 METER_SLIDER_LOW_BRIGHTNESS 1 "Low brightness mode, footwell lights off" 0 "Normal mode, footwell lights on";
VAL_ 1552 METER_SLIDER_DIMMED 1 "Dimmed" 0 "Not Dimmed";
VAL_ 1552 UNITS 1 "km (km/L)" 2 "km (L/100km)" 3 "miles (MPG US)" 4 "miles (MPG Imperial)";
VAL_ 1553 UNITS 1 "km" 2 "miles";
VAL_ 1556 TURN_SIGNALS 3 "none" 2 "right" 1 "left";
VAL_ 1592 LOCK_STATUS 0 "locked" 1 "unlocked";

VAL_ 610 IPAS_STATE 5 "override" 3 "enabled" 1 "disabled";
